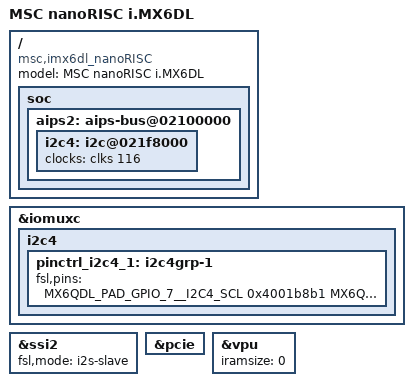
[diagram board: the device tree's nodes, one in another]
/*
 * Copyright (C) 2014 MSC Technologies, Design Center Aachen
 *
 * This program is free software; you can redistribute it and/or modify
 * it under the terms of the GNU General Public License as published by
 * the Free Software Foundation; either version 2 of the License, or
 * (at your option) any later version.

 * This program is distributed in the hope that it will be useful,
 * but WITHOUT ANY WARRANTY; without even the implied warranty of
 * MERCHANTABILITY or FITNESS FOR A PARTICULAR PURPOSE.  See the
 * GNU General Public License for more details.

 * You should have received a copy of the GNU General Public License along
 * with this program; if not, write to the Free Software Foundation, Inc.,
 * 51 Franklin Street, Fifth Floor, Boston, MA 02110-1301 USA.
 */
#include "skeleton.dtsi"
#include "imx6dl-pinfunc.h"
#include "imx6dl.dtsi"
#include "msc-nR-imx6qdl.dtsi"

&iomuxc {
	i2c4 {
		pinctrl_i2c4_1: i2c4grp-1 {
			fsl,pins = <
				MX6QDL_PAD_GPIO_7__I2C4_SCL 0x4001b8b1
				MX6QDL_PAD_GPIO_8__I2C4_SDA 0x4001b8b1
			>;
		};
	};
};

/ {
	model = "MSC nanoRISC i.MX6DL";
	compatible = "msc,imx6dl_nanoRISC", "fsl,imx6dl";

	soc {
		aips2: aips-bus@02100000 {
			i2c4: i2c@021f8000 {
				clocks = <&clks 116>;
			};
		};
	};
};

&ssi2 {
	fsl,mode = "i2s-slave";
	status = "okay";
};

&pcie {
	status = "okay";
};

&vpu {
	iramsize = <0>;
	status = "okay";
};
